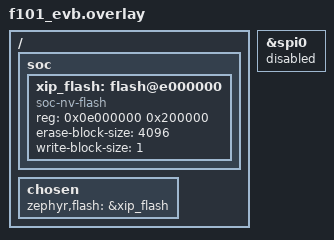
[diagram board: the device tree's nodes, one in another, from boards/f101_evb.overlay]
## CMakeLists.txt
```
# SPDX-License-Identifier: Apache-2.0

cmake_minimum_required(VERSION 3.20.0)
find_package(Zephyr REQUIRED HINTS $ENV{ZEPHYR_BASE})
project(sunxi_spif_xip)

target_sources(app PRIVATE src/main.c)
```

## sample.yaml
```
sample:
  name: XIP from the SPIF flash window
  description: Run the whole image from the memory window of the SPIF controller
tests:
  sample.drivers.flash.sunxi_spif_xip:
    platform_allow:
      - f101_evb
    tags: flash
    build_only: true
```

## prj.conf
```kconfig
# the whole image runs from the flash window of the SPIF controller
CONFIG_XIP=y
CONFIG_LOG=y
CONFIG_SHELL=n
CONFIG_MAIN_STACK_SIZE=4096
```

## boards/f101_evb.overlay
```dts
/*
 * The image is linked into the memory window of the SPIF controller. The
 * window maps the flash from the offset the boot stub programs (boot/) at
 * 0x0e000000.
 */

/ {
	soc {
		xip_flash: flash@e000000 {
			compatible = "soc-nv-flash";
			reg = <0x0e000000 0x200000>;
			erase-block-size = <4096>;
			write-block-size = <1>;
		};
	};

	chosen {
		zephyr,flash = &xip_flash;
	};
};

/* spi0 uses the pins of the flash (PC0..PC5): switching them away would cut the window off */
&spi0 {
	status = "disabled";
};
```

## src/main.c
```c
/*
 * Copyright (c) 2026 Yuzuki Tsuru
 *
 * SPDX-License-Identifier: Apache-2.0
 */

#include <zephyr/kernel.h>
#include <zephyr/sys/printk.h>

extern char __rom_region_start[], __rom_region_end[];

static const char rodata_string[] = "rodata is in the flash window too";
static int counter = 41;	/* .data: copied from the flash to RAM at boot */

int main(void)
{
	printk("XIP: main at %p, image %p..%p, rodata %p, data %p, stack %p\n", (void *)main,
	       __rom_region_start, __rom_region_end, rodata_string, &counter, &(int){ 0 });
	counter++;
	printk("XIP: %s, counter %d (expect 42)\n", rodata_string, counter);
	for (int i = 0; i < 3; i++) {
		printk("XIP: tick %d at %lld ms\n", i, k_uptime_get());
		k_sleep(K_MSEC(200));
	}
	printk("XIP: done\n");

	return 0;
}
```
